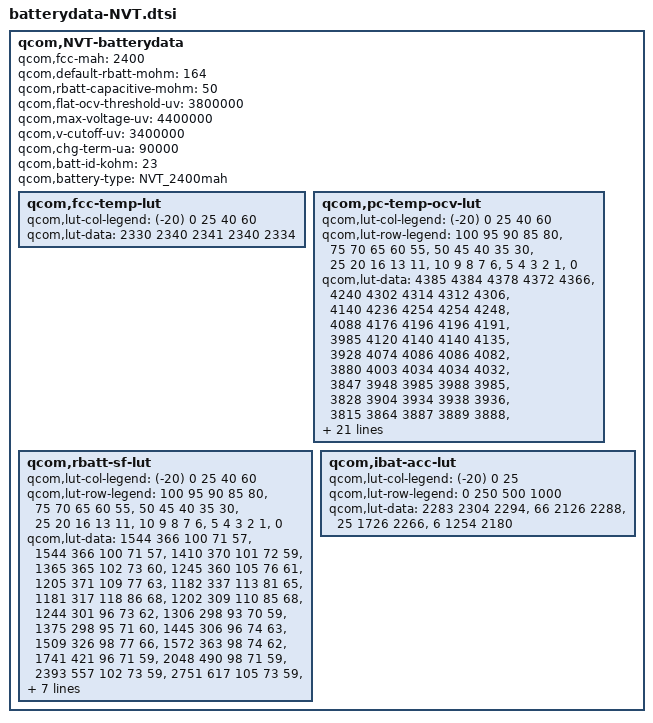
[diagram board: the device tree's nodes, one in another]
/* Copyright (c) 2013-2014, The Linux Foundation. All rights reserved.
 *
 * This program is free software; you can redistribute it and/or modify
 * it under the terms of the GNU General Public License version 2 and
 * only version 2 as published by the Free Software Foundation.
 *
 * This program is distributed in the hope that it will be useful,
 * but WITHOUT ANY WARRANTY; without even the implied warranty of
 * MERCHANTABILITY or FITNESS FOR A PARTICULAR PURPOSE.  See the
 * GNU General Public License for more details.
 */


qcom,NVT-batterydata {


	qcom,fcc-mah = <2400>;
	qcom,default-rbatt-mohm = <164>;
	qcom,rbatt-capacitive-mohm = <50>;
	qcom,flat-ocv-threshold-uv = <3800000>;
	qcom,max-voltage-uv = <4400000>;
	qcom,v-cutoff-uv = <3400000>;
	qcom,chg-term-ua = <90000>;
	qcom,batt-id-kohm = <23>;
	qcom,battery-type = "NVT_2400mah";

	qcom,fcc-temp-lut {
		qcom,lut-col-legend = <(-20) 0 25 40 60>;
		qcom,lut-data = <2330 2340 2341 2340 2334>;
	};

	qcom,pc-temp-ocv-lut {
		qcom,lut-col-legend = <(-20) 0 25 40 60>;
		qcom,lut-row-legend = <100 95 90 85 80>,
				<75 70 65 60 55>,
				<50 45 40 35 30>,
				<25 20 16 13 11>,
				<10 9 8 7 6>,
				<5 4 3 2 1>,
				<0>;
		qcom,lut-data = <4385 4384 4378 4372 4366>,
				<4240 4302 4314 4312 4306>,
				<4140 4236 4254 4254 4248>,
				<4088 4176 4196 4196 4191>,
				<3985 4120 4140 4140 4135>,
				<3928 4074 4086 4086 4082>,
				<3880 4003 4034 4034 4032>,
				<3847 3948 3985 3988 3985>,
				<3828 3904 3934 3938 3936>,
				<3815 3864 3887 3889 3888>,
				<3803 3832 3852 3854 3854>,
				<3790 3808 3827 3828 3828>,
				<3776 3791 3806 3807 3806>,
				<3763 3780 3787 3789 3788>,
				<3748 3770 3771 3769 3762>,
				<3732 3757 3754 3747 3736>,
				<3712 3738 3734 3726 3713>,
				<3692 3718 3714 3706 3693>,
				<3674 3701 3697 3689 3676>,
				<3658 3692 3687 3680 3670>,
				<3650 3687 3684 3679 3668>,
				<3640 3682 3682 3678 3667>,
				<3630 3678 3680 3676 3664>,
				<3618 3672 3677 3672 3660>,
				<3600 3662 3668 3660 3644>,
				<3576 3640 3640 3630 3610>,
				<3542 3601 3596 3584 3562>,
				<3490 3544 3536 3525 3502>,
				<3414 3466 3458 3444 3420>,
				<3293 3338 3338 3320 3284>,
				<3028 3000 3000 3000 3000>;
	};

	qcom,rbatt-sf-lut {
		qcom,lut-col-legend = <(-20) 0 25 40 60>;
		qcom,lut-row-legend = <100 95 90 85 80>,
				<75 70 65 60 55>,
				<50 45 40 35 30>,
				<25 20 16 13 11>,
				<10 9 8 7 6>,
				<5 4 3 2 1>,
				<0>;
		qcom,lut-data = <1544 366 100 71 57>,
				<1544 366 100 71 57>,
				<1410 370 101 72 59>,
				<1365 365 102 73 60>,
				<1245 360 105 76 61>,
				<1205 371 109 77 63>,
				<1182 337 113 81 65>,
				<1181 317 118 86 68>,
				<1202 309 110 85 68>,
				<1244 301 96 73 62>,
				<1306 298 93 70 59>,
				<1375 298 95 71 60>,
				<1445 306 96 74 63>,
				<1509 326 98 77 66>,
				<1572 363 98 74 62>,
				<1741 421 96 71 59>,
				<2048 490 98 71 59>,
				<2393 557 102 73 59>,
				<2751 617 105 73 59>,
				<3094 668 107 73 60>,
				<3270 693 110 75 62>,
				<3455 718 113 77 63>,
				<3545 704 113 79 65>,
				<3560 717 116 80 66>,
				<3982 756 118 80 64>,
				<4564 794 116 77 62>,
				<5329 840 120 78 63>,
				<6456 909 128 82 66>,
				<8389 998 143 90 74>,
				<16254 1384 177 116 112>,
				<32507 2768 354 233 224>;
	};


	qcom,ibat-acc-lut {
		qcom,lut-col-legend = <(-20) 0 25>;
		qcom,lut-row-legend = <0 250 500 1000>;
		qcom,lut-data = <2283 2304 2294>,
				<66 2126 2288>,
				<25 1726 2266>,
				<6 1254 2180>;
	};


};
